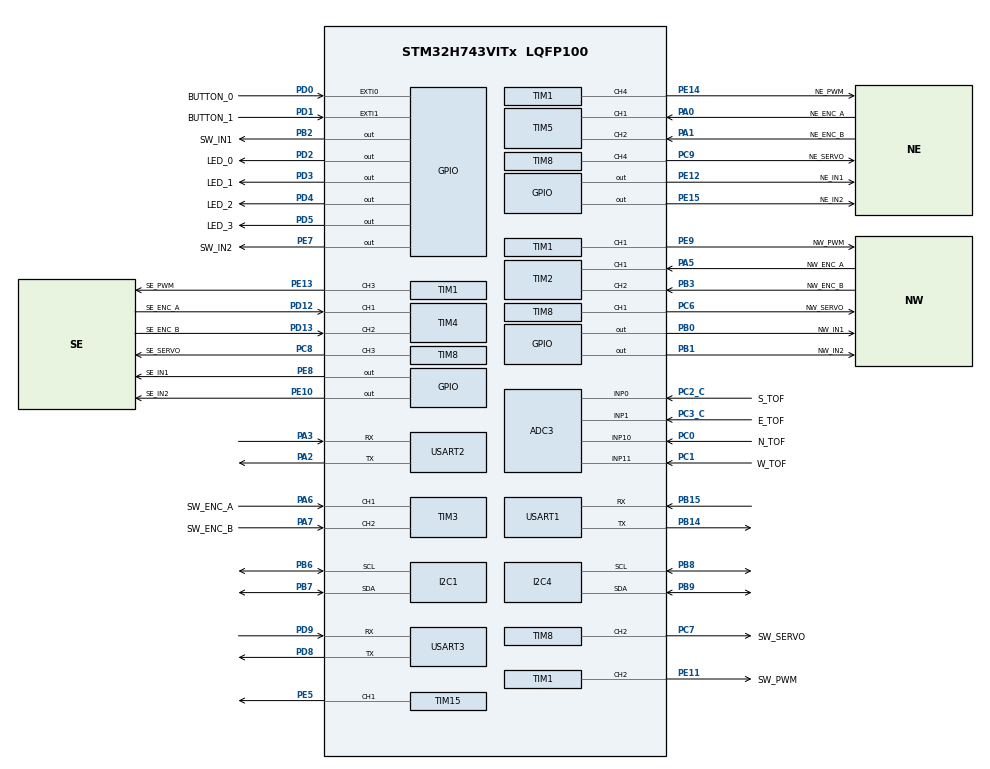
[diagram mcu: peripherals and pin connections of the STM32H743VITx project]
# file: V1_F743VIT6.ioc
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ADC3.Channel-0\#ChannelRegularConversion=ADC_CHANNEL_0
ADC3.Channel-1\#ChannelRegularConversion=ADC_CHANNEL_1
ADC3.Channel-2\#ChannelRegularConversion=ADC_CHANNEL_10
ADC3.Channel-3\#ChannelRegularConversion=ADC_CHANNEL_11
ADC3.NbrOfConversion=4
ADC3.NbrOfConversionFlag=1
ADC3.OffsetNumber-0\#ChannelRegularConversion=ADC_OFFSET_NONE
ADC3.OffsetNumber-1\#ChannelRegularConversion=ADC_OFFSET_NONE
ADC3.OffsetNumber-2\#ChannelRegularConversion=ADC_OFFSET_NONE
ADC3.OffsetNumber-3\#ChannelRegularConversion=ADC_OFFSET_NONE
ADC3.OffsetSignedSaturation-0\#ChannelRegularConversion=DISABLE
ADC3.OffsetSignedSaturation-1\#ChannelRegularConversion=DISABLE
ADC3.OffsetSignedSaturation-2\#ChannelRegularConversion=DISABLE
ADC3.OffsetSignedSaturation-3\#ChannelRegularConversion=DISABLE
ADC3.Rank-0\#ChannelRegularConversion=1
ADC3.Rank-1\#ChannelRegularConversion=2
ADC3.Rank-2\#ChannelRegularConversion=3
ADC3.Rank-3\#ChannelRegularConversion=4
ADC3.SamplingTime-0\#ChannelRegularConversion=ADC_SAMPLETIME_64CYCLES_5
ADC3.SamplingTime-1\#ChannelRegularConversion=ADC_SAMPLETIME_64CYCLES_5
ADC3.SamplingTime-2\#ChannelRegularConversion=ADC_SAMPLETIME_64CYCLES_5
ADC3.SamplingTime-3\#ChannelRegularConversion=ADC_SAMPLETIME_64CYCLES_5
Bdma.ADC3.0.Direction=DMA_PERIPH_TO_MEMORY
Bdma.ADC3.0.EventEnable=DISABLE
Bdma.ADC3.0.Instance=BDMA_Channel0
Bdma.ADC3.0.MemDataAlignment=DMA_MDATAALIGN_HALFWORD
Bdma.ADC3.0.MemInc=DMA_MINC_ENABLE
Bdma.ADC3.0.Mode=DMA_CIRCULAR
Bdma.ADC3.0.PeriphDataAlignment=DMA_PDATAALIGN_HALFWORD
Bdma.ADC3.0.PeriphInc=DMA_PINC_DISABLE
Bdma.ADC3.0.Polarity=HAL_DMAMUX_REQ_GEN_RISING
Bdma.ADC3.0.Priority=DMA_PRIORITY_LOW
Bdma.ADC3.0.RequestNumber=1
Bdma.ADC3.0.SignalID=NONE
Bdma.ADC3.0.SyncEnable=DISABLE
Bdma.ADC3.0.SyncPolarity=HAL_DMAMUX_SYNC_NO_EVENT
Bdma.ADC3.0.SyncRequestNumber=1
Bdma.ADC3.0.SyncSignalID=NONE
Bdma.Request0=ADC3
Bdma.RequestsNb=1
CORTEX_M7.default_mode_Activation=1
I2C1.Timing=0x307075B1
I2C4.Timing=0x307075B1
Mcu.Family=STM32H7
Mcu.Name=STM32H743VITx
Mcu.Package=LQFP100
NVIC.BDMA_Channel0_IRQn=true\:0\:0\:false\:false\:true\:false\:true\:true
NVIC.PriorityGroup=NVIC_PRIORITYGROUP_4
PA0.GPIO_Label=NE_ENC_A
PA0.Signal=S_TIM5_CH1
PA1.GPIO_Label=NE_ENC_B
PA1.Signal=S_TIM5_CH2
PA13\ (JTMS/SWDIO).Mode=Serial_Wire
PA13\ (JTMS/SWDIO).Signal=DEBUG_JTMS-SWDIO
PA14\ (JTCK/SWCLK).Mode=Serial_Wire
PA14\ (JTCK/SWCLK).Signal=DEBUG_JTCK-SWCLK
PA2.Mode=Asynchronous
PA2.Signal=USART2_TX
PA3.Mode=Asynchronous
PA3.Signal=USART2_RX
PA5.GPIO_Label=NW_ENC_A
PA5.Signal=S_TIM2_CH1_ETR
PA6.GPIO_Label=SW_ENC_A
PA6.Signal=S_TIM3_CH1
PA7.GPIO_Label=SW_ENC_B
PA7.Signal=S_TIM3_CH2
PB0.GPIO_Label=NW_IN1
PB0.Signal=GPIO_Output
PB1.GPIO_Label=NW_IN2
PB1.Signal=GPIO_Output
PB14.Mode=Asynchronous
PB14.Signal=USART1_TX
PB15.Mode=Asynchronous
PB15.Signal=USART1_RX
PB2.GPIO_Label=SW_IN1
PB2.Signal=GPIO_Output
PB3\ (JTDO/TRACESWO).GPIO_Label=NW_ENC_B
PB3\ (JTDO/TRACESWO).Signal=S_TIM2_CH2
PB6.Mode=I2C
PB6.Signal=I2C1_SCL
PB7.Mode=I2C
PB7.Signal=I2C1_SDA
PB8.Mode=I2C
PB8.Signal=I2C4_SCL
PB9.Mode=I2C
PB9.Signal=I2C4_SDA
PC0.GPIO_Label=N_TOF
PC0.Signal=ADCx_INP10
PC1.GPIO_Label=W_TOF
PC1.Signal=ADCx_INP11
PC2_C.GPIO_Label=S_TOF
PC2_C.Mode=IN0-Single-Ended
PC2_C.Signal=ADC3_INP0
PC3_C.GPIO_Label=E_TOF
PC3_C.Mode=IN1-Single-Ended
PC3_C.Signal=ADC3_INP1
PC6.GPIO_Label=NW_SERVO
PC6.Signal=S_TIM8_CH1
PC7.GPIO_Label=SW_SERVO
PC7.Signal=S_TIM8_CH2
PC8.GPIO_Label=SE_SERVO
PC8.Signal=S_TIM8_CH3
PC9.GPIO_Label=NE_SERVO
PC9.Signal=S_TIM8_CH4
PD0.GPIO_Label=BUTTON_0
PD0.Signal=GPXTI0
PD1.GPIO_Label=BUTTON_1
PD1.Signal=GPXTI1
PD12.GPIO_Label=SE_ENC_A
PD12.Signal=S_TIM4_CH1
PD13.GPIO_Label=SE_ENC_B
PD13.Signal=S_TIM4_CH2
PD2.GPIO_Label=LED_0
PD2.Signal=GPIO_Output
PD3.GPIO_Label=LED_1
PD3.Signal=GPIO_Output
PD4.GPIO_Label=LED_2
PD4.Signal=GPIO_Output
PD5.GPIO_Label=LED_3
PD5.Signal=GPIO_Output
PD8.Mode=Asynchronous
PD8.Signal=USART3_TX
PD9.Mode=Asynchronous
PD9.Signal=USART3_RX
PE10.GPIO_Label=SE_IN2
PE10.Signal=GPIO_Output
PE11.GPIO_Label=SW_PWM
PE11.Signal=S_TIM1_CH2
PE12.GPIO_Label=NE_IN1
PE12.Signal=GPIO_Output
PE13.GPIO_Label=SE_PWM
PE13.Signal=S_TIM1_CH3
PE14.GPIO_Label=NE_PWM
PE14.Signal=S_TIM1_CH4
PE15.GPIO_Label=NE_IN2
PE15.Signal=GPIO_Output
PE5.Signal=S_TIM15_CH1
PE7.GPIO_Label=SW_IN2
PE7.Signal=GPIO_Output
PE8.GPIO_Label=SE_IN1
PE8.Signal=GPIO_Output
PE9.GPIO_Label=NW_PWM
PE9.Signal=S_TIM1_CH1
PH0-OSC_IN\ (PH0).Mode=HSE-External-Oscillator
PH0-OSC_IN\ (PH0).Signal=RCC_OSC_IN
PH1-OSC_OUT\ (PH1).Mode=HSE-External-Oscillator
PH1-OSC_OUT\ (PH1).Signal=RCC_OSC_OUT
ProjectManager.HeapSize=0x200
ProjectManager.StackSize=0x400
ProjectManager.TargetToolchain=CMake
RCC.ADCFreq_Value=96750000
RCC.APB1Freq_Value=120000000
RCC.APB2Freq_Value=120000000
RCC.APB3Freq_Value=120000000
RCC.APB4Freq_Value=120000000
RCC.CortexFreq_Value=480000000
RCC.D1PPRE=RCC_APB3_DIV2
RCC.D2PPRE1=RCC_APB1_DIV2
RCC.D2PPRE2=RCC_APB2_DIV2
RCC.D3PPRE=RCC_APB4_DIV2
RCC.DIVM1=3
RCC.DIVN1=60
RCC.HCLKFreq_Value=240000000
RCC.HPRE=RCC_HCLK_DIV2
RCC.HSE_VALUE=48000000
RCC.PLLFRACN=0
RCC.PLLSourceVirtual=RCC_PLLSOURCE_HSE
RCC.SYSCLKFreq_VALUE=480000000
RCC.SYSCLKSource=RCC_SYSCLKSOURCE_PLLCLK
RCC.USBFreq_Value=480000000
SH.ADCx_INP10.0=ADC3_INP10,IN10-Single-Ended
SH.ADCx_INP11.0=ADC3_INP11,IN11-Single-Ended
SH.S_TIM15_CH1.0=TIM15_CH1,PWM Generation1 CH1
SH.S_TIM1_CH1.0=TIM1_CH1,PWM Generation1 CH1
SH.S_TIM1_CH2.0=TIM1_CH2,PWM Generation2 CH2
SH.S_TIM1_CH3.0=TIM1_CH3,PWM Generation3 CH3
SH.S_TIM1_CH4.0=TIM1_CH4,PWM Generation4 CH4
SH.S_TIM2_CH1_ETR.0=TIM2_CH1,Encoder_Interface
SH.S_TIM2_CH2.0=TIM2_CH2,Encoder_Interface
SH.S_TIM3_CH1.0=TIM3_CH1,Encoder_Interface
SH.S_TIM3_CH2.0=TIM3_CH2,Encoder_Interface
SH.S_TIM4_CH1.0=TIM4_CH1,Encoder_Interface
SH.S_TIM4_CH2.0=TIM4_CH2,Encoder_Interface
SH.S_TIM5_CH1.0=TIM5_CH1,Encoder_Interface
SH.S_TIM5_CH2.0=TIM5_CH2,Encoder_Interface
SH.S_TIM8_CH1.0=TIM8_CH1,PWM Generation1 CH1
SH.S_TIM8_CH2.0=TIM8_CH2,PWM Generation2 CH2
SH.S_TIM8_CH3.0=TIM8_CH3,PWM Generation3 CH3
SH.S_TIM8_CH4.0=TIM8_CH4,PWM Generation4 CH4
TIM1.Channel-PWM\ Generation1\ CH1=TIM_CHANNEL_1
TIM1.Channel-PWM\ Generation2\ CH2=TIM_CHANNEL_2
TIM1.Channel-PWM\ Generation3\ CH3=TIM_CHANNEL_3
TIM1.Channel-PWM\ Generation4\ CH4=TIM_CHANNEL_4
TIM15.Channel-PWM\ Generation1\ CH1=TIM_CHANNEL_1
TIM8.Channel-PWM\ Generation1\ CH1=TIM_CHANNEL_1
TIM8.Channel-PWM\ Generation2\ CH2=TIM_CHANNEL_2
TIM8.Channel-PWM\ Generation3\ CH3=TIM_CHANNEL_3
TIM8.Channel-PWM\ Generation4\ CH4=TIM_CHANNEL_4
USART1.VirtualMode-Asynchronous=VM_ASYNC
USART2.VirtualMode-Asynchronous=VM_ASYNC
USART3.VirtualMode-Asynchronous=VM_ASYNC
VP_MEMORYMAP_VS_MEMORYMAP.Mode=CurAppReg
VP_TIM8_VS_ClockSourceINT.Mode=Internal
board=custom

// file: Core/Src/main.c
/* USER CODE BEGIN Header */
/**
  ******************************************************************************
  * @file           : main.c
  * @brief          : Main program body
  ******************************************************************************
  * @attention
  *
  * Copyright (c) 2024 STMicroelectronics.
  * All rights reserved.
  *
  * This software is licensed under terms that can be found in the LICENSE file
  * in the root directory of this software component.
  * If no LICENSE file comes with this software, it is provided AS-IS.
  *
  ******************************************************************************
  */
/* USER CODE END Header */
#include "main.h"

ADC_HandleTypeDef hadc3;
DMA_HandleTypeDef hdma_adc3;

I2C_HandleTypeDef hi2c1;
I2C_HandleTypeDef hi2c4;

TIM_HandleTypeDef htim1;
TIM_HandleTypeDef htim2;
TIM_HandleTypeDef htim3;
TIM_HandleTypeDef htim4;
TIM_HandleTypeDef htim5;
TIM_HandleTypeDef htim8;
TIM_HandleTypeDef htim15;

UART_HandleTypeDef huart1;
UART_HandleTypeDef huart2;
UART_HandleTypeDef huart3;

void SystemClock_Config(void);
static void MPU_Config(void);
static void MX_GPIO_Init(void);
static void MX_BDMA_Init(void);
static void MX_TIM1_Init(void);
static void MX_TIM2_Init(void);
static void MX_TIM3_Init(void);
static void MX_TIM4_Init(void);
static void MX_I2C1_Init(void);
static void MX_I2C4_Init(void);
static void MX_USART1_UART_Init(void);
static void MX_USART3_UART_Init(void);
static void MX_ADC3_Init(void);
static void MX_USART2_UART_Init(void);
static void MX_TIM5_Init(void);
static void MX_TIM8_Init(void);
static void MX_TIM15_Init(void);

int main(void)
{

  /* MPU Configuration--------------------------------------------------------*/
  MPU_Config();

  /* MCU Configuration--------------------------------------------------------*/

  /* Reset of all peripherals, Initializes the Flash interface and the Systick. */
  HAL_Init();

  /* Configure the system clock */
  SystemClock_Config();

  /* Initialize all configured peripherals */
  MX_GPIO_Init();
  MX_BDMA_Init();
  MX_TIM1_Init();
  MX_TIM2_Init();
  MX_TIM3_Init();
  MX_TIM4_Init();
  MX_I2C1_Init();
  MX_I2C4_Init();
  MX_USART1_UART_Init();
  MX_USART3_UART_Init();
  MX_ADC3_Init();
  MX_USART2_UART_Init();
  MX_TIM5_Init();
  MX_TIM8_Init();
  MX_TIM15_Init();

  /* Infinite loop */
  /* USER CODE BEGIN WHILE */
  while (1)
  {
    int a = 100;

    /* USER CODE END WHILE */

  }
}

void SystemClock_Config(void)
{
  RCC_OscInitTypeDef RCC_OscInitStruct = {0};
  RCC_ClkInitTypeDef RCC_ClkInitStruct = {0};

  /** Supply configuration update enable
  */
  HAL_PWREx_ConfigSupply(PWR_LDO_SUPPLY);

  /** Configure the main internal regulator output voltage
  */
  __HAL_PWR_VOLTAGESCALING_CONFIG(PWR_REGULATOR_VOLTAGE_SCALE1);

  while(!__HAL_PWR_GET_FLAG(PWR_FLAG_VOSRDY)) {}

  __HAL_RCC_SYSCFG_CLK_ENABLE();
  __HAL_PWR_VOLTAGESCALING_CONFIG(PWR_REGULATOR_VOLTAGE_SCALE0);

  while(!__HAL_PWR_GET_FLAG(PWR_FLAG_VOSRDY)) {}

  /** Initializes the RCC Oscillators according to the specified parameters
  * in the RCC_OscInitTypeDef structure.
  */
  RCC_OscInitStruct.OscillatorType = RCC_OSCILLATORTYPE_HSE;
  RCC_OscInitStruct.HSEState = RCC_HSE_ON;
  RCC_OscInitStruct.PLL.PLLState = RCC_PLL_ON;
  RCC_OscInitStruct.PLL.PLLSource = RCC_PLLSOURCE_HSE;
  RCC_OscInitStruct.PLL.PLLM = 3;
  RCC_OscInitStruct.PLL.PLLN = 60;
  RCC_OscInitStruct.PLL.PLLP = 2;
  RCC_OscInitStruct.PLL.PLLQ = 2;
  RCC_OscInitStruct.PLL.PLLR = 2;
  RCC_OscInitStruct.PLL.PLLRGE = RCC_PLL1VCIRANGE_3;
  RCC_OscInitStruct.PLL.PLLVCOSEL = RCC_PLL1VCOWIDE;
  RCC_OscInitStruct.PLL.PLLFRACN = 0;
  if (HAL_RCC_OscConfig(&RCC_OscInitStruct) != HAL_OK)
  {
    Error_Handler();
  }

  /** Initializes the CPU, AHB and APB buses clocks
  */
  RCC_ClkInitStruct.ClockType = RCC_CLOCKTYPE_HCLK|RCC_CLOCKTYPE_SYSCLK
                              |RCC_CLOCKTYPE_PCLK1|RCC_CLOCKTYPE_PCLK2
                              |RCC_CLOCKTYPE_D3PCLK1|RCC_CLOCKTYPE_D1PCLK1;
  RCC_ClkInitStruct.SYSCLKSource = RCC_SYSCLKSOURCE_PLLCLK;
  RCC_ClkInitStruct.SYSCLKDivider = RCC_SYSCLK_DIV1;
  RCC_ClkInitStruct.AHBCLKDivider = RCC_HCLK_DIV2;
  RCC_ClkInitStruct.APB3CLKDivider = RCC_APB3_DIV2;
  RCC_ClkInitStruct.APB1CLKDivider = RCC_APB1_DIV2;
  RCC_ClkInitStruct.APB2CLKDivider = RCC_APB2_DIV2;
  RCC_ClkInitStruct.APB4CLKDivider = RCC_APB4_DIV2;

  if (HAL_RCC_ClockConfig(&RCC_ClkInitStruct, FLASH_LATENCY_4) != HAL_OK)
  {
    Error_Handler();
  }
}

static void MX_ADC3_Init(void)
{

  ADC_ChannelConfTypeDef sConfig = {0};

  /** Common config
  */
  hadc3.Instance = ADC3;
  hadc3.Init.ClockPrescaler = ADC_CLOCK_ASYNC_DIV1;
  hadc3.Init.ScanConvMode = ADC_SCAN_ENABLE;
  hadc3.Init.EOCSelection = ADC_EOC_SINGLE_CONV;
  hadc3.Init.LowPowerAutoWait = DISABLE;
  hadc3.Init.ContinuousConvMode = DISABLE;
  hadc3.Init.NbrOfConversion = 4;
  hadc3.Init.DiscontinuousConvMode = DISABLE;
  hadc3.Init.ExternalTrigConv = ADC_SOFTWARE_START;
  hadc3.Init.ExternalTrigConvEdge = ADC_EXTERNALTRIGCONVEDGE_NONE;
  hadc3.Init.ConversionDataManagement = ADC_CONVERSIONDATA_DR;
  hadc3.Init.Overrun = ADC_OVR_DATA_PRESERVED;
  hadc3.Init.LeftBitShift = ADC_LEFTBITSHIFT_NONE;
  hadc3.Init.OversamplingMode = DISABLE;
  hadc3.Init.Oversampling.Ratio = 1;
  if (HAL_ADC_Init(&hadc3) != HAL_OK)
  {
    Error_Handler();
  }
  hadc3.Init.Resolution = ADC_RESOLUTION_16B;
  if (HAL_ADC_Init(&hadc3) != HAL_OK)
  {
    Error_Handler();
  }

  /** Configure Regular Channel
  */
  sConfig.Channel = ADC_CHANNEL_0;
  sConfig.Rank = ADC_REGULAR_RANK_1;
  sConfig.SamplingTime = ADC_SAMPLETIME_64CYCLES_5;
  sConfig.SingleDiff = ADC_SINGLE_ENDED;
  sConfig.OffsetNumber = ADC_OFFSET_NONE;
  sConfig.Offset = 0;
  sConfig.OffsetSignedSaturation = DISABLE;
  if (HAL_ADC_ConfigChannel(&hadc3, &sConfig) != HAL_OK)
  {
    Error_Handler();
  }

  /** Configure Regular Channel
  */
  sConfig.Channel = ADC_CHANNEL_1;
  sConfig.Rank = ADC_REGULAR_RANK_2;
  if (HAL_ADC_ConfigChannel(&hadc3, &sConfig) != HAL_OK)
  {
    Error_Handler();
  }

  /** Configure Regular Channel
  */
  sConfig.Channel = ADC_CHANNEL_10;
  sConfig.Rank = ADC_REGULAR_RANK_3;
  if (HAL_ADC_ConfigChannel(&hadc3, &sConfig) != HAL_OK)
  {
    Error_Handler();
  }

  /** Configure Regular Channel
  */
  sConfig.Channel = ADC_CHANNEL_11;
  sConfig.Rank = ADC_REGULAR_RANK_4;
  if (HAL_ADC_ConfigChannel(&hadc3, &sConfig) != HAL_OK)
  {
    Error_Handler();
  }

}

static void MX_I2C1_Init(void)
{

  hi2c1.Instance = I2C1;
  hi2c1.Init.Timing = 0x307075B1;
  hi2c1.Init.OwnAddress1 = 0;
  hi2c1.Init.AddressingMode = I2C_ADDRESSINGMODE_7BIT;
  hi2c1.Init.DualAddressMode = I2C_DUALADDRESS_DISABLE;
  hi2c1.Init.OwnAddress2 = 0;
  hi2c1.Init.OwnAddress2Masks = I2C_OA2_NOMASK;
  hi2c1.Init.GeneralCallMode = I2C_GENERALCALL_DISABLE;
  hi2c1.Init.NoStretchMode = I2C_NOSTRETCH_DISABLE;
  if (HAL_I2C_Init(&hi2c1) != HAL_OK)
  {
    Error_Handler();
  }

  /** Configure Analogue filter
  */
  if (HAL_I2CEx_ConfigAnalogFilter(&hi2c1, I2C_ANALOGFILTER_ENABLE) != HAL_OK)
  {
    Error_Handler();
  }

  /** Configure Digital filter
  */
  if (HAL_I2CEx_ConfigDigitalFilter(&hi2c1, 0) != HAL_OK)
  {
    Error_Handler();
  }

}

static void MX_I2C4_Init(void)
{

  hi2c4.Instance = I2C4;
  hi2c4.Init.Timing = 0x307075B1;
  hi2c4.Init.OwnAddress1 = 0;
  hi2c4.Init.AddressingMode = I2C_ADDRESSINGMODE_7BIT;
  hi2c4.Init.DualAddressMode = I2C_DUALADDRESS_DISABLE;
  hi2c4.Init.OwnAddress2 = 0;
  hi2c4.Init.OwnAddress2Masks = I2C_OA2_NOMASK;
  hi2c4.Init.GeneralCallMode = I2C_GENERALCALL_DISABLE;
  hi2c4.Init.NoStretchMode = I2C_NOSTRETCH_DISABLE;
  if (HAL_I2C_Init(&hi2c4) != HAL_OK)
  {
    Error_Handler();
  }

  /** Configure Analogue filter
  */
  if (HAL_I2CEx_ConfigAnalogFilter(&hi2c4, I2C_ANALOGFILTER_ENABLE) != HAL_OK)
  {
    Error_Handler();
  }

  /** Configure Digital filter
  */
  if (HAL_I2CEx_ConfigDigitalFilter(&hi2c4, 0) != HAL_OK)
  {
    Error_Handler();
  }

}

static void MX_TIM1_Init(void)
{

  TIM_MasterConfigTypeDef sMasterConfig = {0};
  TIM_OC_InitTypeDef sConfigOC = {0};
  TIM_BreakDeadTimeConfigTypeDef sBreakDeadTimeConfig = {0};

  htim1.Instance = TIM1;
  htim1.Init.Prescaler = 0;
  htim1.Init.CounterMode = TIM_COUNTERMODE_UP;
  htim1.Init.Period = 65535;
  htim1.Init.ClockDivision = TIM_CLOCKDIVISION_DIV1;
  htim1.Init.RepetitionCounter = 0;
  htim1.Init.AutoReloadPreload = TIM_AUTORELOAD_PRELOAD_DISABLE;
  if (HAL_TIM_PWM_Init(&htim1) != HAL_OK)
  {
    Error_Handler();
  }
  sMasterConfig.MasterOutputTrigger = TIM_TRGO_RESET;
  sMasterConfig.MasterOutputTrigger2 = TIM_TRGO2_RESET;
  sMasterConfig.MasterSlaveMode = TIM_MASTERSLAVEMODE_DISABLE;
  if (HAL_TIMEx_MasterConfigSynchronization(&htim1, &sMasterConfig) != HAL_OK)
  {
    Error_Handler();
  }
  sConfigOC.OCMode = TIM_OCMODE_PWM1;
  sConfigOC.Pulse = 0;
  sConfigOC.OCPolarity = TIM_OCPOLARITY_HIGH;
  sConfigOC.OCNPolarity = TIM_OCNPOLARITY_HIGH;
  sConfigOC.OCFastMode = TIM_OCFAST_DISABLE;
  sConfigOC.OCIdleState = TIM_OCIDLESTATE_RESET;
  sConfigOC.OCNIdleState = TIM_OCNIDLESTATE_RESET;
  if (HAL_TIM_PWM_ConfigChannel(&htim1, &sConfigOC, TIM_CHANNEL_1) != HAL_OK)
  {
    Error_Handler();
  }
  if (HAL_TIM_PWM_ConfigChannel(&htim1, &sConfigOC, TIM_CHANNEL_2) != HAL_OK)
  {
    Error_Handler();
  }
  if (HAL_TIM_PWM_ConfigChannel(&htim1, &sConfigOC, TIM_CHANNEL_3) != HAL_OK)
  {
    Error_Handler();
  }
  if (HAL_TIM_PWM_ConfigChannel(&htim1, &sConfigOC, TIM_CHANNEL_4) != HAL_OK)
  {
    Error_Handler();
  }
  sBreakDeadTimeConfig.OffStateRunMode = TIM_OSSR_DISABLE;
  sBreakDeadTimeConfig.OffStateIDLEMode = TIM_OSSI_DISABLE;
  sBreakDeadTimeConfig.LockLevel = TIM_LOCKLEVEL_OFF;
  sBreakDeadTimeConfig.DeadTime = 0;
  sBreakDeadTimeConfig.BreakState = TIM_BREAK_DISABLE;
  sBreakDeadTimeConfig.BreakPolarity = TIM_BREAKPOLARITY_HIGH;
  sBreakDeadTimeConfig.BreakFilter = 0;
  sBreakDeadTimeConfig.Break2State = TIM_BREAK2_DISABLE;
  sBreakDeadTimeConfig.Break2Polarity = TIM_BREAK2POLARITY_HIGH;
  sBreakDeadTimeConfig.Break2Filter = 0;
  sBreakDeadTimeConfig.AutomaticOutput = TIM_AUTOMATICOUTPUT_DISABLE;
  if (HAL_TIMEx_ConfigBreakDeadTime(&htim1, &sBreakDeadTimeConfig) != HAL_OK)
  {
    Error_Handler();
  }
  HAL_TIM_MspPostInit(&htim1);

}

static void MX_TIM2_Init(void)
{

  TIM_Encoder_InitTypeDef sConfig = {0};
  TIM_MasterConfigTypeDef sMasterConfig = {0};

  htim2.Instance = TIM2;
  htim2.Init.Prescaler = 0;
  htim2.Init.CounterMode = TIM_COUNTERMODE_UP;
  htim2.Init.Period = 4294967295;
  htim2.Init.ClockDivision = TIM_CLOCKDIVISION_DIV1;
  htim2.Init.AutoReloadPreload = TIM_AUTORELOAD_PRELOAD_DISABLE;
  sConfig.EncoderMode = TIM_ENCODERMODE_TI1;
  sConfig.IC1Polarity = TIM_ICPOLARITY_RISING;
  sConfig.IC1Selection = TIM_ICSELECTION_DIRECTTI;
  sConfig.IC1Prescaler = TIM_ICPSC_DIV1;
  sConfig.IC1Filter = 0;
  sConfig.IC2Polarity = TIM_ICPOLARITY_RISING;
  sConfig.IC2Selection = TIM_ICSELECTION_DIRECTTI;
  sConfig.IC2Prescaler = TIM_ICPSC_DIV1;
  sConfig.IC2Filter = 0;
  if (HAL_TIM_Encoder_Init(&htim2, &sConfig) != HAL_OK)
  {
    Error_Handler();
  }
  sMasterConfig.MasterOutputTrigger = TIM_TRGO_RESET;
  sMasterConfig.MasterSlaveMode = TIM_MASTERSLAVEMODE_DISABLE;
  if (HAL_TIMEx_MasterConfigSynchronization(&htim2, &sMasterConfig) != HAL_OK)
  {
    Error_Handler();
  }

}

static void MX_TIM3_Init(void)
{

  TIM_Encoder_InitTypeDef sConfig = {0};
  TIM_MasterConfigTypeDef sMasterConfig = {0};

  htim3.Instance = TIM3;
  htim3.Init.Prescaler = 0;
  htim3.Init.CounterMode = TIM_COUNTERMODE_UP;
  htim3.Init.Period = 65535;
  htim3.Init.ClockDivision = TIM_CLOCKDIVISION_DIV1;
  htim3.Init.AutoReloadPreload = TIM_AUTORELOAD_PRELOAD_DISABLE;
  sConfig.EncoderMode = TIM_ENCODERMODE_TI1;
  sConfig.IC1Polarity = TIM_ICPOLARITY_RISING;
  sConfig.IC1Selection = TIM_ICSELECTION_DIRECTTI;
  sConfig.IC1Prescaler = TIM_ICPSC_DIV1;
  sConfig.IC1Filter = 0;
  sConfig.IC2Polarity = TIM_ICPOLARITY_RISING;
  sConfig.IC2Selection = TIM_ICSELECTION_DIRECTTI;
  sConfig.IC2Prescaler = TIM_ICPSC_DIV1;
  sConfig.IC2Filter = 0;
  if (HAL_TIM_Encoder_Init(&htim3, &sConfig) != HAL_OK)
  {
    Error_Handler();
  }
  sMasterConfig.MasterOutputTrigger = TIM_TRGO_RESET;
  sMasterConfig.MasterSlaveMode = TIM_MASTERSLAVEMODE_DISABLE;
  if (HAL_TIMEx_MasterConfigSynchronization(&htim3, &sMasterConfig) != HAL_OK)
  {
    Error_Handler();
  }

}

static void MX_TIM4_Init(void)
{

  TIM_Encoder_InitTypeDef sConfig = {0};
  TIM_MasterConfigTypeDef sMasterConfig = {0};

  htim4.Instance = TIM4;
  htim4.Init.Prescaler = 0;
  htim4.Init.CounterMode = TIM_COUNTERMODE_UP;
  htim4.Init.Period = 65535;
  htim4.Init.ClockDivision = TIM_CLOCKDIVISION_DIV1;
  htim4.Init.AutoReloadPreload = TIM_AUTORELOAD_PRELOAD_DISABLE;
  sConfig.EncoderMode = TIM_ENCODERMODE_TI1;
  sConfig.IC1Polarity = TIM_ICPOLARITY_RISING;
  sConfig.IC1Selection = TIM_ICSELECTION_DIRECTTI;
  sConfig.IC1Prescaler = TIM_ICPSC_DIV1;
  sConfig.IC1Filter = 0;
  sConfig.IC2Polarity = TIM_ICPOLARITY_RISING;
  sConfig.IC2Selection = TIM_ICSELECTION_DIRECTTI;
  sConfig.IC2Prescaler = TIM_ICPSC_DIV1;
  sConfig.IC2Filter = 0;
  if (HAL_TIM_Encoder_Init(&htim4, &sConfig) != HAL_OK)
  {
    Error_Handler();
  }
  sMasterConfig.MasterOutputTrigger = TIM_TRGO_RESET;
  sMasterConfig.MasterSlaveMode = TIM_MASTERSLAVEMODE_DISABLE;
  if (HAL_TIMEx_MasterConfigSynchronization(&htim4, &sMasterConfig) != HAL_OK)
  {
    Error_Handler();
  }

}

static void MX_TIM5_Init(void)
{

  TIM_Encoder_InitTypeDef sConfig = {0};
  TIM_MasterConfigTypeDef sMasterConfig = {0};

  htim5.Instance = TIM5;
  htim5.Init.Prescaler = 0;
  htim5.Init.CounterMode = TIM_COUNTERMODE_UP;
  htim5.Init.Period = 4294967295;
  htim5.Init.ClockDivision = TIM_CLOCKDIVISION_DIV1;
  htim5.Init.AutoReloadPreload = TIM_AUTORELOAD_PRELOAD_DISABLE;
  sConfig.EncoderMode = TIM_ENCODERMODE_TI1;
  sConfig.IC1Polarity = TIM_ICPOLARITY_RISING;
  sConfig.IC1Selection = TIM_ICSELECTION_DIRECTTI;
  sConfig.IC1Prescaler = TIM_ICPSC_DIV1;
  sConfig.IC1Filter = 0;
  sConfig.IC2Polarity = TIM_ICPOLARITY_RISING;
  sConfig.IC2Selection = TIM_ICSELECTION_DIRECTTI;
  sConfig.IC2Prescaler = TIM_ICPSC_DIV1;
  sConfig.IC2Filter = 0;
  if (HAL_TIM_Encoder_Init(&htim5, &sConfig) != HAL_OK)
  {
    Error_Handler();
  }
  sMasterConfig.MasterOutputTrigger = TIM_TRGO_RESET;
  sMasterConfig.MasterSlaveMode = TIM_MASTERSLAVEMODE_DISABLE;
  if (HAL_TIMEx_MasterConfigSynchronization(&htim5, &sMasterConfig) != HAL_OK)
  {
    Error_Handler();
  }

}

static void MX_TIM8_Init(void)
{

  TIM_ClockConfigTypeDef sClockSourceConfig = {0};
  TIM_MasterConfigTypeDef sMasterConfig = {0};
  TIM_OC_InitTypeDef sConfigOC = {0};
  TIM_BreakDeadTimeConfigTypeDef sBreakDeadTimeConfig = {0};

  htim8.Instance = TIM8;
  htim8.Init.Prescaler = 0;
  htim8.Init.CounterMode = TIM_COUNTERMODE_UP;
  htim8.Init.Period = 65535;
  htim8.Init.ClockDivision = TIM_CLOCKDIVISION_DIV1;
  htim8.Init.RepetitionCounter = 0;
  htim8.Init.AutoReloadPreload = TIM_AUTORELOAD_PRELOAD_DISABLE;
  if (HAL_TIM_Base_Init(&htim8) != HAL_OK)
  {
    Error_Handler();
  }
  sClockSourceConfig.ClockSource = TIM_CLOCKSOURCE_INTERNAL;
  if (HAL_TIM_ConfigClockSource(&htim8, &sClockSourceConfig) != HAL_OK)
  {
    Error_Handler();
  }
  if (HAL_TIM_PWM_Init(&htim8) != HAL_OK)
  {
    Error_Handler();
  }
  sMasterConfig.MasterOutputTrigger = TIM_TRGO_RESET;
  sMasterConfig.MasterOutputTrigger2 = TIM_TRGO2_RESET;
  sMasterConfig.MasterSlaveMode = TIM_MASTERSLAVEMODE_DISABLE;
  if (HAL_TIMEx_MasterConfigSynchronization(&htim8, &sMasterConfig) != HAL_OK)
  {
    Error_Handler();
  }
  sConfigOC.OCMode = TIM_OCMODE_PWM1;
  sConfigOC.Pulse = 0;
  sConfigOC.OCPolarity = TIM_OCPOLARITY_HIGH;
  sConfigOC.OCNPolarity = TIM_OCNPOLARITY_HIGH;
  sConfigOC.OCFastMode = TIM_OCFAST_DISABLE;
  sConfigOC.OCIdleState = TIM_OCIDLESTATE_RESET;
  sConfigOC.OCNIdleState = TIM_OCNIDLESTATE_RESET;
  if (HAL_TIM_PWM_ConfigChannel(&htim8, &sConfigOC, TIM_CHANNEL_1) != HAL_OK)
  {
    Error_Handler();
  }
  if (HAL_TIM_PWM_ConfigChannel(&htim8, &sConfigOC, TIM_CHANNEL_2) != HAL_OK)
  {
    Error_Handler();
  }
  if (HAL_TIM_PWM_ConfigChannel(&htim8, &sConfigOC, TIM_CHANNEL_3) != HAL_OK)
  {
    Error_Handler();
  }
  if (HAL_TIM_PWM_ConfigChannel(&htim8, &sConfigOC, TIM_CHANNEL_4) != HAL_OK)
  {
    Error_Handler();
  }
  sBreakDeadTimeConfig.OffStateRunMode = TIM_OSSR_DISABLE;
  sBreakDeadTimeConfig.OffStateIDLEMode = TIM_OSSI_DISABLE;
  sBreakDeadTimeConfig.LockLevel = TIM_LOCKLEVEL_OFF;
  sBreakDeadTimeConfig.DeadTime = 0;
  sBreakDeadTimeConfig.BreakState = TIM_BREAK_DISABLE;
  sBreakDeadTimeConfig.BreakPolarity = TIM_BREAKPOLARITY_HIGH;
  sBreakDeadTimeConfig.BreakFilter = 0;
  sBreakDeadTimeConfig.Break2State = TIM_BREAK2_DISABLE;
  sBreakDeadTimeConfig.Break2Polarity = TIM_BREAK2POLARITY_HIGH;
  sBreakDeadTimeConfig.Break2Filter = 0;
  sBreakDeadTimeConfig.AutomaticOutput = TIM_AUTOMATICOUTPUT_DISABLE;
  if (HAL_TIMEx_ConfigBreakDeadTime(&htim8, &sBreakDeadTimeConfig) != HAL_OK)
  {
    Error_Handler();
  }
  HAL_TIM_MspPostInit(&htim8);

}

static void MX_TIM15_Init(void)
{

  TIM_MasterConfigTypeDef sMasterConfig = {0};
  TIM_OC_InitTypeDef sConfigOC = {0};
  TIM_BreakDeadTimeConfigTypeDef sBreakDeadTimeConfig = {0};

  htim15.Instance = TIM15;
  htim15.Init.Prescaler = 0;
  htim15.Init.CounterMode = TIM_COUNTERMODE_UP;
  htim15.Init.Period = 65535;
  htim15.Init.ClockDivision = TIM_CLOCKDIVISION_DIV1;
  htim15.Init.RepetitionCounter = 0;
  htim15.Init.AutoReloadPreload = TIM_AUTORELOAD_PRELOAD_DISABLE;
  if (HAL_TIM_PWM_Init(&htim15) != HAL_OK)
  {
    Error_Handler();
  }
  sMasterConfig.MasterOutputTrigger = TIM_TRGO_RESET;
  sMasterConfig.MasterSlaveMode = TIM_MASTERSLAVEMODE_DISABLE;
  if (HAL_TIMEx_MasterConfigSynchronization(&htim15, &sMasterConfig) != HAL_OK)
  {
    Error_Handler();
  }
  sConfigOC.OCMode = TIM_OCMODE_PWM1;
  sConfigOC.Pulse = 0;
  sConfigOC.OCPolarity = TIM_OCPOLARITY_HIGH;
  sConfigOC.OCNPolarity = TIM_OCNPOLARITY_HIGH;
  sConfigOC.OCFastMode = TIM_OCFAST_DISABLE;
  sConfigOC.OCIdleState = TIM_OCIDLESTATE_RESET;
  sConfigOC.OCNIdleState = TIM_OCNIDLESTATE_RESET;
  if (HAL_TIM_PWM_ConfigChannel(&htim15, &sConfigOC, TIM_CHANNEL_1) != HAL_OK)
  {
    Error_Handler();
  }
  sBreakDeadTimeConfig.OffStateRunMode = TIM_OSSR_DISABLE;
  sBreakDeadTimeConfig.OffStateIDLEMode = TIM_OSSI_DISABLE;
  sBreakDeadTimeConfig.LockLevel = TIM_LOCKLEVEL_OFF;
  sBreakDeadTimeConfig.DeadTime = 0;
  sBreakDeadTimeConfig.BreakState = TIM_BREAK_DISABLE;
  sBreakDeadTimeConfig.BreakPolarity = TIM_BREAKPOLARITY_HIGH;
  sBreakDeadTimeConfig.BreakFilter = 0;
  sBreakDeadTimeConfig.AutomaticOutput = TIM_AUTOMATICOUTPUT_DISABLE;
  if (HAL_TIMEx_ConfigBreakDeadTime(&htim15, &sBreakDeadTimeConfig) != HAL_OK)
  {
    Error_Handler();
  }
  HAL_TIM_MspPostInit(&htim15);

}

static void MX_USART1_UART_Init(void)
{

  huart1.Instance = USART1;
  huart1.Init.BaudRate = 115200;
  huart1.Init.WordLength = UART_WORDLENGTH_8B;
  huart1.Init.StopBits = UART_STOPBITS_1;
  huart1.Init.Parity = UART_PARITY_NONE;
  huart1.Init.Mode = UART_MODE_TX_RX;
  huart1.Init.HwFlowCtl = UART_HWCONTROL_NONE;
  huart1.Init.OverSampling = UART_OVERSAMPLING_16;
  huart1.Init.OneBitSampling = UART_ONE_BIT_SAMPLE_DISABLE;
  huart1.Init.ClockPrescaler = UART_PRESCALER_DIV1;
  huart1.AdvancedInit.AdvFeatureInit = UART_ADVFEATURE_NO_INIT;
  if (HAL_UART_Init(&huart1) != HAL_OK)
  {
    Error_Handler();
  }
  if (HAL_UARTEx_SetTxFifoThreshold(&huart1, UART_TXFIFO_THRESHOLD_1_8) != HAL_OK)
  {
    Error_Handler();
  }
  if (HAL_UARTEx_SetRxFifoThreshold(&huart1, UART_RXFIFO_THRESHOLD_1_8) != HAL_OK)
  {
    Error_Handler();
  }
  if (HAL_UARTEx_DisableFifoMode(&huart1) != HAL_OK)
  {
    Error_Handler();
  }

}

static void MX_USART2_UART_Init(void)
{

  huart2.Instance = USART2;
  huart2.Init.BaudRate = 115200;
  huart2.Init.WordLength = UART_WORDLENGTH_8B;
  huart2.Init.StopBits = UART_STOPBITS_1;
  huart2.Init.Parity = UART_PARITY_NONE;
  huart2.Init.Mode = UART_MODE_TX_RX;
  huart2.Init.HwFlowCtl = UART_HWCONTROL_NONE;
  huart2.Init.OverSampling = UART_OVERSAMPLING_16;
  huart2.Init.OneBitSampling = UART_ONE_BIT_SAMPLE_DISABLE;
  huart2.Init.ClockPrescaler = UART_PRESCALER_DIV1;
  huart2.AdvancedInit.AdvFeatureInit = UART_ADVFEATURE_NO_INIT;
  if (HAL_UART_Init(&huart2) != HAL_OK)
  {
    Error_Handler();
  }
  if (HAL_UARTEx_SetTxFifoThreshold(&huart2, UART_TXFIFO_THRESHOLD_1_8) != HAL_OK)
  {
    Error_Handler();
  }
  if (HAL_UARTEx_SetRxFifoThreshold(&huart2, UART_RXFIFO_THRESHOLD_1_8) != HAL_OK)
  {
    Error_Handler();
  }
  if (HAL_UARTEx_DisableFifoMode(&huart2) != HAL_OK)
  {
    Error_Handler();
  }

}

static void MX_USART3_UART_Init(void)
{

  huart3.Instance = USART3;
  huart3.Init.BaudRate = 115200;
  huart3.Init.WordLength = UART_WORDLENGTH_8B;
  huart3.Init.StopBits = UART_STOPBITS_1;
  huart3.Init.Parity = UART_PARITY_NONE;
  huart3.Init.Mode = UART_MODE_TX_RX;
  huart3.Init.HwFlowCtl = UART_HWCONTROL_NONE;
  huart3.Init.OverSampling = UART_OVERSAMPLING_16;
  huart3.Init.OneBitSampling = UART_ONE_BIT_SAMPLE_DISABLE;
  huart3.Init.ClockPrescaler = UART_PRESCALER_DIV1;
  huart3.AdvancedInit.AdvFeatureInit = UART_ADVFEATURE_NO_INIT;
  if (HAL_UART_Init(&huart3) != HAL_OK)
  {
    Error_Handler();
  }
  if (HAL_UARTEx_SetTxFifoThreshold(&huart3, UART_TXFIFO_THRESHOLD_1_8) != HAL_OK)
  {
    Error_Handler();
  }
  if (HAL_UARTEx_SetRxFifoThreshold(&huart3, UART_RXFIFO_THRESHOLD_1_8) != HAL_OK)
  {
    Error_Handler();
  }
  if (HAL_UARTEx_DisableFifoMode(&huart3) != HAL_OK)
  {
    Error_Handler();
  }

}

static void MX_BDMA_Init(void)
{

  /* DMA controller clock enable */
  __HAL_RCC_BDMA_CLK_ENABLE();

  /* DMA interrupt init */
  /* BDMA_Channel0_IRQn interrupt configuration */
  HAL_NVIC_SetPriority(BDMA_Channel0_IRQn, 0, 0);
  HAL_NVIC_EnableIRQ(BDMA_Channel0_IRQn);

}

static void MX_GPIO_Init(void)
{
  GPIO_InitTypeDef GPIO_InitStruct = {0};

  /* GPIO Ports Clock Enable */
  __HAL_RCC_GPIOE_CLK_ENABLE();
  __HAL_RCC_GPIOH_CLK_ENABLE();
  __HAL_RCC_GPIOC_CLK_ENABLE();
  __HAL_RCC_GPIOA_CLK_ENABLE();
  __HAL_RCC_GPIOB_CLK_ENABLE();
  __HAL_RCC_GPIOD_CLK_ENABLE();

  /*Configure GPIO pin Output Level */
  HAL_GPIO_WritePin(GPIOB, NW_IN1_Pin|NW_IN2_Pin|SW_IN1_Pin, GPIO_PIN_RESET);

  /*Configure GPIO pin Output Level */
  HAL_GPIO_WritePin(GPIOE, SW_IN2_Pin|SE_IN1_Pin|SE_IN2_Pin|NE_IN1_Pin
                          |NE_IN2_Pin, GPIO_PIN_RESET);

  /*Configure GPIO pin Output Level */
  HAL_GPIO_WritePin(GPIOD, LED_0_Pin|LED_1_Pin|LED_2_Pin|LED_3_Pin, GPIO_PIN_RESET);

  /*Configure GPIO pins : NW_IN1_Pin NW_IN2_Pin SW_IN1_Pin */
  GPIO_InitStruct.Pin = NW_IN1_Pin|NW_IN2_Pin|SW_IN1_Pin;
  GPIO_InitStruct.Mode = GPIO_MODE_OUTPUT_PP;
  GPIO_InitStruct.Pull = GPIO_NOPULL;
  GPIO_InitStruct.Speed = GPIO_SPEED_FREQ_LOW;
  HAL_GPIO_Init(GPIOB, &GPIO_InitStruct);

  /*Configure GPIO pins : SW_IN2_Pin SE_IN1_Pin SE_IN2_Pin NE_IN1_Pin
                           NE_IN2_Pin */
  GPIO_InitStruct.Pin = SW_IN2_Pin|SE_IN1_Pin|SE_IN2_Pin|NE_IN1_Pin
                          |NE_IN2_Pin;
  GPIO_InitStruct.Mode = GPIO_MODE_OUTPUT_PP;
  GPIO_InitStruct.Pull = GPIO_NOPULL;
  GPIO_InitStruct.Speed = GPIO_SPEED_FREQ_LOW;
  HAL_GPIO_Init(GPIOE, &GPIO_InitStruct);

  /*Configure GPIO pins : BUTTON_0_Pin BUTTON_1_Pin */
  GPIO_InitStruct.Pin = BUTTON_0_Pin|BUTTON_1_Pin;
  GPIO_InitStruct.Mode = GPIO_MODE_IT_RISING;
  GPIO_InitStruct.Pull = GPIO_NOPULL;
  HAL_GPIO_Init(GPIOD, &GPIO_InitStruct);

  /*Configure GPIO pins : LED_0_Pin LED_1_Pin LED_2_Pin LED_3_Pin */
  GPIO_InitStruct.Pin = LED_0_Pin|LED_1_Pin|LED_2_Pin|LED_3_Pin;
  GPIO_InitStruct.Mode = GPIO_MODE_OUTPUT_PP;
  GPIO_InitStruct.Pull = GPIO_NOPULL;
  GPIO_InitStruct.Speed = GPIO_SPEED_FREQ_LOW;
  HAL_GPIO_Init(GPIOD, &GPIO_InitStruct);

}

 /* MPU Configuration */

void MPU_Config(void)
{
  MPU_Region_InitTypeDef MPU_InitStruct = {0};

  /* Disables the MPU */
  HAL_MPU_Disable();

  /** Initializes and configures the Region and the memory to be protected
  */
  MPU_InitStruct.Enable = MPU_REGION_ENABLE;
  MPU_InitStruct.Number = MPU_REGION_NUMBER0;
  MPU_InitStruct.BaseAddress = 0x0;
  MPU_InitStruct.Size = MPU_REGION_SIZE_4GB;
  MPU_InitStruct.SubRegionDisable = 0x87;
  MPU_InitStruct.TypeExtField = MPU_TEX_LEVEL0;
  MPU_InitStruct.AccessPermission = MPU_REGION_NO_ACCESS;
  MPU_InitStruct.DisableExec = MPU_INSTRUCTION_ACCESS_DISABLE;
  MPU_InitStruct.IsShareable = MPU_ACCESS_SHAREABLE;
  MPU_InitStruct.IsCacheable = MPU_ACCESS_NOT_CACHEABLE;
  MPU_InitStruct.IsBufferable = MPU_ACCESS_NOT_BUFFERABLE;

  HAL_MPU_ConfigRegion(&MPU_InitStruct);
  /* Enables the MPU */
  HAL_MPU_Enable(MPU_PRIVILEGED_DEFAULT);

}

void Error_Handler(void)
{
  __disable_irq();
  while (1)
  {
  }
}
